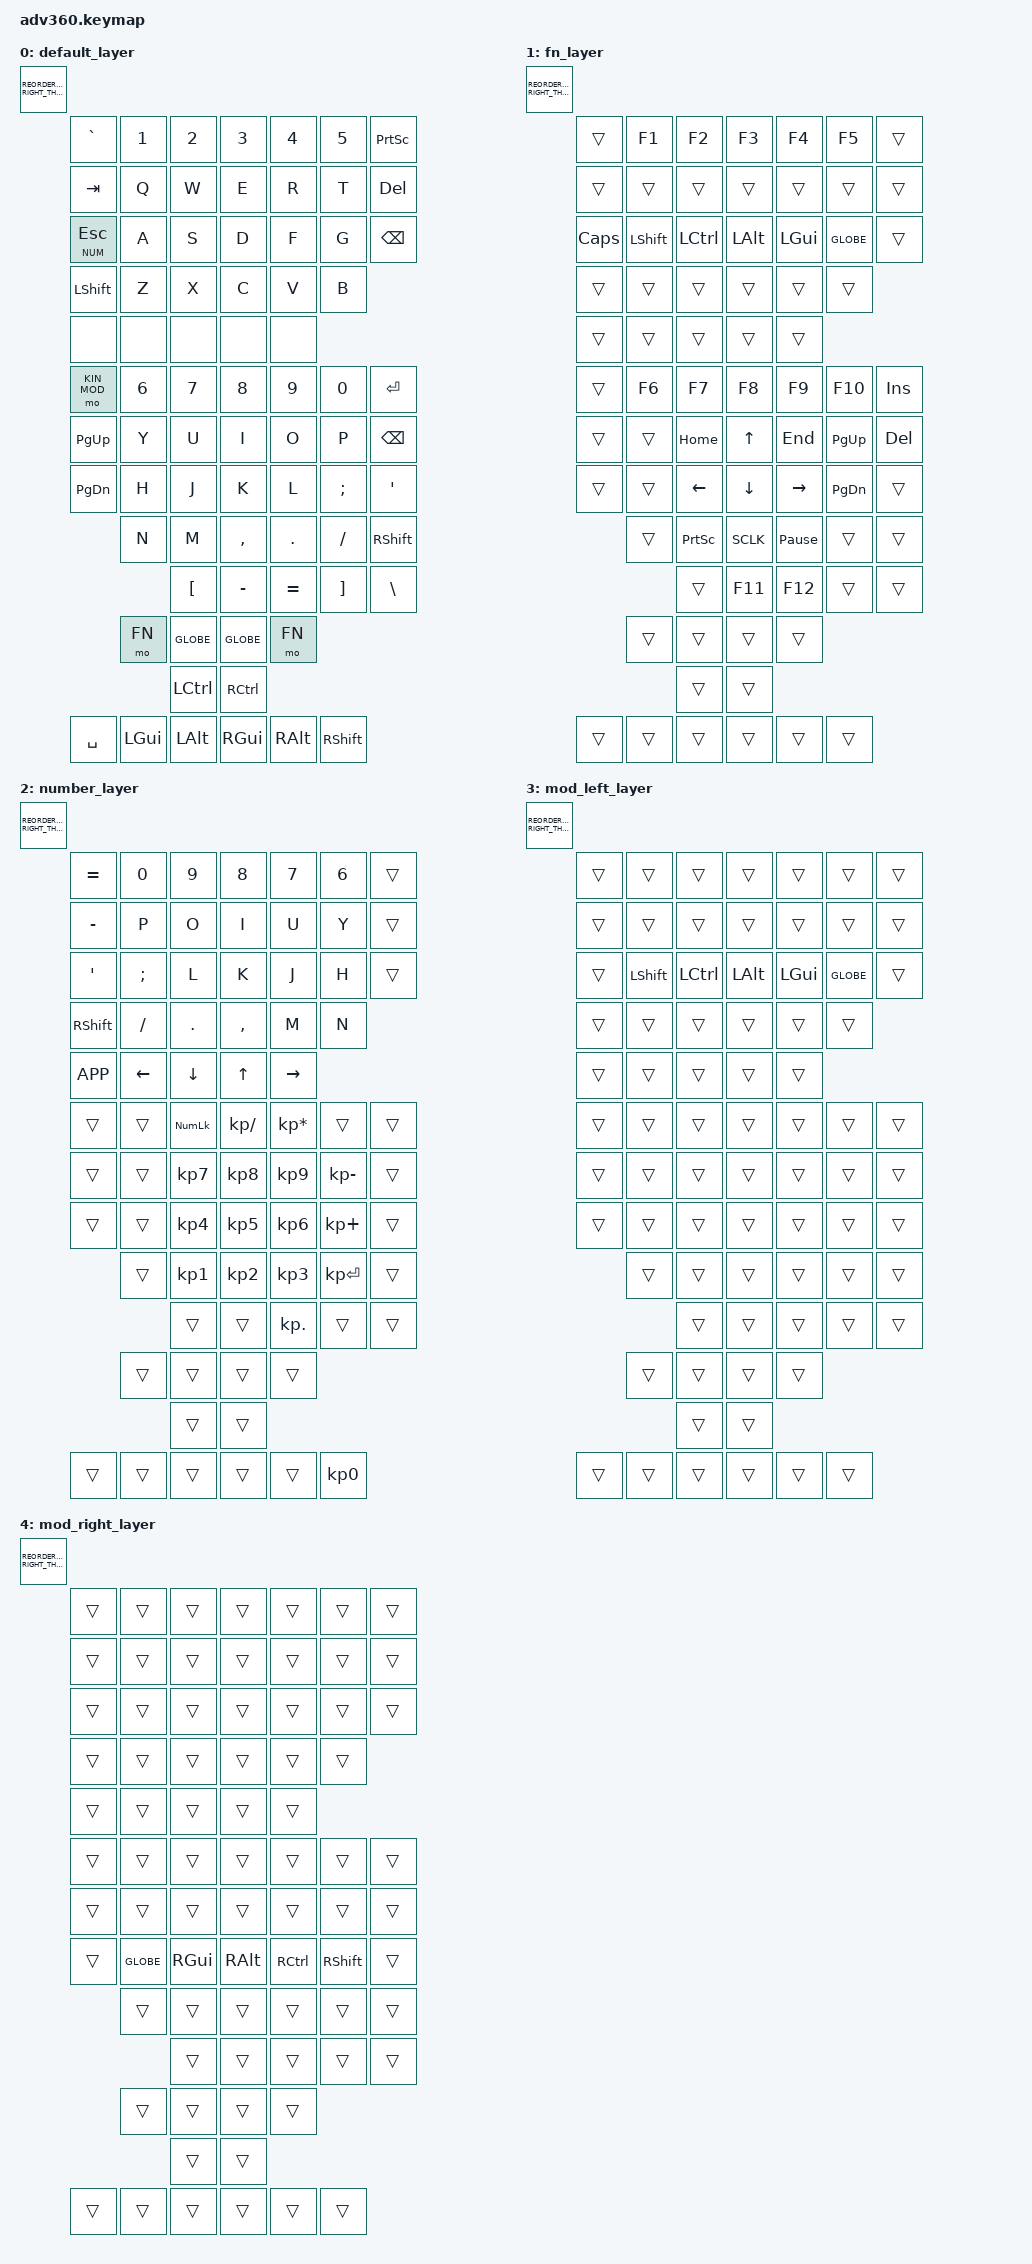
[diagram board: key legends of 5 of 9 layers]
#include <behaviors.dtsi>
#include <dt-bindings/zmk/keys.h>
#include <dt-bindings/zmk/bt.h>
#include <dt-bindings/zmk/rgb.h>
#include <dt-bindings/zmk/stp.h>
#include <dt-bindings/zmk/backlight.h>
#include <dt-bindings/zmk/pointing.h>

// Custom layers
#define DEFAULT 0
#define FN 1
#define NUM 2
#define MOD_LEFT 3
#define MOD_RIGHT 4

// Default Kinesis Advantage 360 Pro layers.
#define KIN_DEF 5
#define KIN_KP 6
#define KIN_FN 7
#define KIN_MOD 8

#define ___ &trans
#define _x_ &none

#define REORDER_LEFT_RIGHT_THUMBS(L1, L2, L3, L4, L5, R1, R2, R3, R4, R5, T3, T4, T5, X) L1 R1 L2 R2 L3 T3 R3 L4 T4 R4 L5 T5 R5

//#include "combos.dtsi"


/ {
    behaviors {
      #include "macros.dtsi"
      #include "version.dtsi"

//      #include "behaviors.dtsi"

      m: mod_hold {
        compatible = "zmk,behavior-hold-tap";
        flavor = "hold-preferred";
        label = "MOD_HOLD";
        #binding-cells = <2>;
        tapping-term-ms = <220>;
        quick-tap-ms = <200>;
        bindings = <&kp>, <&kp>;
      };

      l: layer_hold {
        compatible = "zmk,behavior-hold-tap";
        flavor = "hold-preferred";
        label = "LAYER_HOLD";
        #binding-cells = <2>;
        tapping-term-ms = <220>;
        quick-tap-ms = <200>;
        bindings = <&mo>, <&kp>;
      };
    };

  keymap {
    compatible = "zmk,keymap";

    default_layer {
      bindings = <REORDER_LEFT_RIGHT_THUMBS(
        // ╭─────────────┬─────────────┬─────────────┬─────────────┬─────────────┬─────────────┬─────────────╮
             &kp GRAVE     &kp N1        &kp N2        &kp N3        &kp N4        &kp N5        &kp PSCRN   ,
        // ├─────────────┼─────────────┼─────────────┼─────────────┼─────────────┼─────────────┼─────────────┤
             &kp TAB       &kp Q         &kp W         &kp E         &kp R         &kp T         &kp DEL     ,
        // ├─────────────┼─────────────┼─────────────┼─────────────┼─────────────┼─────────────┼─────────────┤
             &l NUM ESC    &kp A         &kp S         &kp D         &kp F         &kp G         &kp BSPC    ,
        // ├─────────────┼─────────────┼─────────────┼─────────────┼─────────────┼─────────────┼─────────────╯
             &kp LSHFT     &kp Z         &kp X         &kp C         &kp V         &kp B       ,
        // ├─────────────┼─────────────┼─────────────┼─────────────┼─────────────┼─────────────╯
             _x_           _x_           _x_           _x_           _x_         ,
        // ╰─────────────┴─────────────┴─────────────┴─────────────┴─────────────╯
        //
        // ╭─────────────┬─────────────┬─────────────┬─────────────┬─────────────┬─────────────┬─────────────╮
             &mo KIN_MOD   &kp N6        &kp N7        &kp N8        &kp N9        &kp N0        &kp ENTER   ,
        // ├─────────────┼─────────────┼─────────────┼─────────────┼─────────────┼─────────────┼─────────────┤
             &kp PG_UP     &kp Y         &kp U         &kp I         &kp O         &kp P         &kp BSPC    ,
        // ├─────────────┼─────────────┼─────────────┼─────────────┼─────────────┼─────────────┼─────────────┤
             &kp PG_DN     &kp H         &kp J         &kp K         &kp L         &kp SEMI      &kp SQT     ,
        // ╰─────────────┼─────────────┼─────────────┼─────────────┼─────────────┼─────────────┼─────────────┤
                           &kp N         &kp M         &kp COMMA     &kp DOT       &kp FSLH      &kp RSHFT   ,
        //               ╰─────────────┼─────────────┼─────────────┼─────────────┼─────────────┼─────────────┤
                                         &kp LBKT      &kp MINUS     &kp EQUAL     &kp RBKT      &kp BSLH    ,
        //                             ╰─────────────┴─────────────┴─────────────┴─────────────┴─────────────╯
        //
        //               ╭─────────────┬─────────────╮   ╭─────────────┬─────────────╮
                           &mo FN        &kp GLOBE         &kp GLOBE     &mo FN      ,
        // ╭─────────────┼─────────────┼─────────────┤   ├─────────────┼─────────────┼─────────────╮
                                         &kp LCTL          &kp RCTL                                ,
        // │             │             ├─────────────┤   ├─────────────┤             │             │
             &kp SPACE     &kp LGUI      &kp LALT          &kp RGUI      &kp RALT      &kp RSHFT   ,
        // ╰─────────────┴─────────────┴─────────────╯   ╰─────────────┴─────────────┴─────────────╯
      )>;
    };

    fn_layer {
      bindings = <REORDER_LEFT_RIGHT_THUMBS(
        // ╭─────────────┬─────────────┬─────────────┬─────────────┬─────────────┬─────────────┬─────────────╮
             ___           &kp F1        &kp F2        &kp F3        &kp F4        &kp F5        ___         ,
        // ├─────────────┼─────────────┼─────────────┼─────────────┼─────────────┼─────────────┼─────────────┤
             ___           ___           ___           ___           ___           ___           ___         ,
        // ├─────────────┼─────────────┼─────────────┼─────────────┼─────────────┼─────────────┼─────────────┤
             &kp CAPS      &kp LSHFT     &kp LCTRL     &kp LALT      &kp LGUI      &kp GLOBE     ___         ,
        // ├─────────────┼─────────────┼─────────────┼─────────────┼─────────────┼─────────────┼─────────────╯
             ___           ___           ___           ___           ___           ___         ,
        // ├─────────────┼─────────────┼─────────────┼─────────────┼─────────────┼─────────────╯
             ___           ___           ___           ___           ___         ,
        // ╰─────────────┴─────────────┴─────────────┴─────────────┴─────────────╯
        //
        // ╭─────────────┬─────────────┬─────────────┬─────────────┬─────────────┬─────────────┬─────────────╮
             ___           &kp F6        &kp F7        &kp F8        &kp F9        &kp F10       &kp INS     ,
        // ├─────────────┼─────────────┼─────────────┼─────────────┼─────────────┼─────────────┼─────────────┤
             ___           ___           &kp HOME      &kp UP        &kp END       &kp PG_UP     &kp DEL     ,
        // ├─────────────┼─────────────┼─────────────┼─────────────┼─────────────┼─────────────┼─────────────┤
             ___           ___           &kp LEFT      &kp DOWN      &kp RIGHT     &kp PG_DN     ___         ,
        // ╰─────────────┼─────────────┼─────────────┼─────────────┼─────────────┼─────────────┼─────────────┤
                           ___           &kp PSCRN     &kp SCLK    &kp PAUSE_BREAK ___           ___         ,
        //               ╰─────────────┼─────────────┼─────────────┼─────────────┼─────────────┼─────────────┤
                                         ___           &kp F11       &kp F12       ___           ___         ,
        //                             ╰─────────────┴─────────────┴─────────────┴─────────────┴─────────────╯
        //
        //               ╭─────────────┬─────────────╮   ╭─────────────┬─────────────╮
                           ___           ___               ___           ___         ,
        // ╭─────────────┼─────────────┼─────────────┤   ├─────────────┼─────────────┼─────────────╮
                                         ___               ___                                     ,
        // │             │             ├─────────────┤   ├─────────────┤             │             │
             ___           ___           ___               ___           ___           ___         ,
        // ╰─────────────┴─────────────┴─────────────╯   ╰─────────────┴─────────────┴─────────────╯
      )>;
    };

    number_layer {
      bindings = <REORDER_LEFT_RIGHT_THUMBS(
        // ╭─────────────┬─────────────┬─────────────┬─────────────┬─────────────┬─────────────┬─────────────╮
             &kp EQUAL     &kp N0        &kp N9        &kp N8        &kp N7        &kp N6        ___         ,
        // ├─────────────┼─────────────┼─────────────┼─────────────┼─────────────┼─────────────┼─────────────┤
             &kp MINUS     &kp P         &kp O         &kp I         &kp U         &kp Y         ___         ,
        // ├─────────────┼─────────────┼─────────────┼─────────────┼─────────────┼─────────────┼─────────────┤
             &kp SQT       &kp SEMI      &kp L         &kp K         &kp J         &kp H         ___         ,
        // ├─────────────┼─────────────┼─────────────┼─────────────┼─────────────┼─────────────┼─────────────╯
             &kp RSHFT     &kp FSLH      &kp DOT       &kp COMMA     &kp M         &kp N       ,
        // ├─────────────┼─────────────┼─────────────┼─────────────┼─────────────┼─────────────╯
             &kp K_APP     &kp LEFT      &kp DOWN      &kp UP        &kp RIGHT   ,
        // ╰─────────────┴─────────────┴─────────────┴─────────────┴─────────────╯
        //
        // ╭─────────────┬─────────────┬─────────────┬─────────────┬─────────────┬─────────────┬─────────────╮
             ___           ___           &kp KP_NUM    &kp KP_DIVIDE &kp KP_MULTIPLY ___         ___         ,
        // ├─────────────┼─────────────┼─────────────┼─────────────┼─────────────┼─────────────┼─────────────┤
             ___           ___           &kp KP_N7     &kp KP_N8     &kp KP_N9     &kp KP_MINUS  ___         ,
        // ├─────────────┼─────────────┼─────────────┼─────────────┼─────────────┼─────────────┼─────────────┤
             ___           ___           &kp KP_N4     &kp KP_N5     &kp KP_N6     &kp KP_PLUS   ___         ,
        // ╰─────────────┼─────────────┼─────────────┼─────────────┼─────────────┼─────────────┼─────────────┤
                           ___           &kp KP_N1     &kp KP_N2     &kp KP_N3     &kp KP_ENTER  ___         ,
        //               ╰─────────────┼─────────────┼─────────────┼─────────────┼─────────────┼─────────────┤
                                         ___           ___           &kp KP_DOT    ___           ___         ,
        //                             ╰─────────────┴─────────────┴─────────────┴─────────────┴─────────────╯
        //
        //               ╭─────────────┬─────────────╮   ╭─────────────┬─────────────╮
                           ___           ___               ___           ___         ,
        // ╭─────────────┼─────────────┼─────────────┤   ├─────────────┼─────────────┼─────────────╮
                                         ___               ___                                     ,
        // │             │             ├─────────────┤   ├─────────────┤             │             │
             ___           ___           ___               ___           ___           &kp KP_N0   ,
        // ╰─────────────┴─────────────┴─────────────╯   ╰─────────────┴─────────────┴─────────────╯
      )>;
    };

    mod_left_layer {
      bindings = <REORDER_LEFT_RIGHT_THUMBS(
        // ╭─────────────┬─────────────┬─────────────┬─────────────┬─────────────┬─────────────┬─────────────╮
             ___           ___           ___           ___           ___           ___           ___         ,
        // ├─────────────┼─────────────┼─────────────┼─────────────┼─────────────┼─────────────┼─────────────┤
             ___           ___           ___           ___           ___           ___           ___         ,
        // ├─────────────┼─────────────┼─────────────┼─────────────┼─────────────┼─────────────┼─────────────┤
             ___           &kp LSHFT     &kp LCTRL     &kp LALT      &kp LGUI      &kp GLOBE     ___         ,
        // ├─────────────┼─────────────┼─────────────┼─────────────┼─────────────┼─────────────┼─────────────╯
             ___           ___           ___           ___           ___           ___         ,
        // ├─────────────┼─────────────┼─────────────┼─────────────┼─────────────┼─────────────╯
             ___           ___           ___           ___           ___         ,
        // ╰─────────────┴─────────────┴─────────────┴─────────────┴─────────────╯
        //
        // ╭─────────────┬─────────────┬─────────────┬─────────────┬─────────────┬─────────────┬─────────────╮
             ___           ___           ___           ___           ___           ___           ___         ,
        // ├─────────────┼─────────────┼─────────────┼─────────────┼─────────────┼─────────────┼─────────────┤
             ___           ___           ___           ___           ___           ___           ___         ,
        // ├─────────────┼─────────────┼─────────────┼─────────────┼─────────────┼─────────────┼─────────────┤
             ___           ___           ___           ___           ___           ___           ___         ,
        // ╰─────────────┼─────────────┼─────────────┼─────────────┼─────────────┼─────────────┼─────────────┤
                           ___           ___           ___           ___           ___           ___         ,
        //               ╰─────────────┼─────────────┼─────────────┼─────────────┼─────────────┼─────────────┤
                                         ___           ___           ___           ___           ___         ,
        //                             ╰─────────────┴─────────────┴─────────────┴─────────────┴─────────────╯
        //
        //               ╭─────────────┬─────────────╮   ╭─────────────┬─────────────╮
                           ___           ___               ___           ___         ,
        // ╭─────────────┼─────────────┼─────────────┤   ├─────────────┼─────────────┼─────────────╮
                                         ___               ___                                     ,
        // │             │             ├─────────────┤   ├─────────────┤             │             │
             ___           ___           ___               ___           ___           ___         ,
        // ╰─────────────┴─────────────┴─────────────╯   ╰─────────────┴─────────────┴─────────────╯
      )>;
    };

    mod_right_layer {
      bindings = <REORDER_LEFT_RIGHT_THUMBS(
        // ╭─────────────┬─────────────┬─────────────┬─────────────┬─────────────┬─────────────┬─────────────╮
             ___           ___           ___           ___           ___           ___           ___         ,
        // ├─────────────┼─────────────┼─────────────┼─────────────┼─────────────┼─────────────┼─────────────┤
             ___           ___           ___           ___           ___           ___           ___         ,
        // ├─────────────┼─────────────┼─────────────┼─────────────┼─────────────┼─────────────┼─────────────┤
             ___           ___           ___           ___           ___           ___           ___         ,
        // ├─────────────┼─────────────┼─────────────┼─────────────┼─────────────┼─────────────┼─────────────╯
             ___           ___           ___           ___           ___           ___         ,
        // ├─────────────┼─────────────┼─────────────┼─────────────┼─────────────┼─────────────╯
             ___           ___           ___           ___           ___         ,
        // ╰─────────────┴─────────────┴─────────────┴─────────────┴─────────────╯
        //
        // ╭─────────────┬─────────────┬─────────────┬─────────────┬─────────────┬─────────────┬─────────────╮
             ___           ___           ___           ___           ___           ___           ___         ,
        // ├─────────────┼─────────────┼─────────────┼─────────────┼─────────────┼─────────────┼─────────────┤
             ___           ___           ___           ___           ___           ___           ___         ,
        // ├─────────────┼─────────────┼─────────────┼─────────────┼─────────────┼─────────────┼─────────────┤
             ___           &kp GLOBE     &kp RGUI      &kp RALT      &kp RCTRL     &kp RSHFT     ___         ,
        // ╰─────────────┼─────────────┼─────────────┼─────────────┼─────────────┼─────────────┼─────────────┤
                           ___           ___           ___           ___           ___           ___         ,
        //               ╰─────────────┼─────────────┼─────────────┼─────────────┼─────────────┼─────────────┤
                                         ___           ___           ___           ___           ___         ,
        //                             ╰─────────────┴─────────────┴─────────────┴─────────────┴─────────────╯
        //
        //               ╭─────────────┬─────────────╮   ╭─────────────┬─────────────╮
                           ___           ___               ___           ___         ,
        // ╭─────────────┼─────────────┼─────────────┤   ├─────────────┼─────────────┼─────────────╮
                                         ___               ___                                     ,
        // │             │             ├─────────────┤   ├─────────────┤             │             │
             ___           ___           ___               ___           ___           ___         ,
        // ╰─────────────┴─────────────┴─────────────╯   ╰─────────────┴─────────────┴─────────────╯
      )>;
    };


    // Default Kinesis Advantage 360 Pro layers.
    kinesis_default_layer {
      display-name = "Base";
      bindings = <
        // ╭─────────────┬─────────────┬─────────────┬─────────────┬─────────────┬─────────────┬─────────────╮                                                                                             ╭─────────────┬─────────────┬─────────────┬─────────────┬─────────────┬─────────────┬─────────────╮
             &kp EQUAL     &kp N1        &kp N2        &kp N3        &kp N4        &kp N5        &tog KIN_KP                                                                                                 &mo KIN_MOD   &kp N6        &kp N7        &kp N8        &kp N9        &kp N0        &kp MINUS
        // ├─────────────┼─────────────┼─────────────┼─────────────┼─────────────┼─────────────┼─────────────┤                                                                                             ├─────────────┼─────────────┼─────────────┼─────────────┼─────────────┼─────────────┼─────────────┤
             &kp TAB       &kp Q         &kp W         &kp E         &kp R         &kp T         _x_                                                                                                         _x_           &kp Y         &kp U         &kp I         &kp O         &kp P         &kp BSLH
        // ├─────────────┼─────────────┼─────────────┼─────────────┼─────────────┼─────────────┼─────────────┤                ╭─────────────┬─────────────╮   ╭─────────────┬─────────────╮                ├─────────────┼─────────────┼─────────────┼─────────────┼─────────────┼─────────────┼─────────────┤
             &kp ESC       &kp A         &kp S         &kp D         &kp F         &kp G         _x_                            &kp LCTRL     &kp LALT          &kp LGUI      &kp RCTRL                      _x_           &kp H         &kp J         &kp K         &kp L         &kp SEMI      &kp SQT
        // ├─────────────┼─────────────┼─────────────┼─────────────┼─────────────┼─────────────┼─────────────╯  ╭─────────────┼─────────────┼─────────────┤   ├─────────────┼─────────────┼─────────────╮  ╰─────────────┼─────────────┼─────────────┼─────────────┼─────────────┼─────────────┼─────────────┤
             &kp LSHFT     &kp Z         &kp X         &kp C         &kp V         &kp B                                                      &kp HOME          &kp PG_UP                                                  &kp N         &kp M         &kp COMMA     &kp DOT       &kp FSLH      &kp RSHFT
        // ├─────────────┼─────────────┼─────────────┼─────────────┼─────────────┼─────────────╯                │             │             ├─────────────┤   ├─────────────┤             │             │                ╰─────────────┼─────────────┼─────────────┼─────────────┼─────────────┼─────────────┤
             &mo KIN_FN    &kp GRAVE     &kp CAPS      &kp LEFT      &kp RIGHT                                    &kp BSPC      &kp DEL       &kp END           &kp PG_DN     &kp ENTER     &kp SPACE                                    &kp UP        &kp DOWN      &kp LBKT      &kp RBKT      &mo KIN_FN
        // ╰─────────────┴─────────────┴─────────────┴─────────────┴─────────────╯                              ╰─────────────┴─────────────┴─────────────╯   ╰─────────────┴─────────────┴─────────────╯                              ╰─────────────┴─────────────┴─────────────┴─────────────┴─────────────╯
      >;
    };
    kinesis_keypad {
      display-name = "Kp";
      bindings = <
        // ╭─────────────┬─────────────┬─────────────┬─────────────┬─────────────┬─────────────┬─────────────╮                                                                                             ╭─────────────┬─────────────┬─────────────┬─────────────┬─────────────┬─────────────┬─────────────╮
             &kp EQUAL     &kp N1        &kp N2        &kp N3        &kp N4        &kp N5        ___                                                                                                         &mo KIN_MOD   &kp N6        &kp KP_NUM    &kp KP_EQUAL  &kp KP_DIVIDE &kp KP_MULTIPLY &kp MINUS
        // ├─────────────┼─────────────┼─────────────┼─────────────┼─────────────┼─────────────┼─────────────┤                                                                                             ├─────────────┼─────────────┼─────────────┼─────────────┼─────────────┼─────────────┼─────────────┤
             &kp TAB       &kp Q         &kp W         &kp E         &kp R         &kp T         _x_                                                                                                         _x_           &kp Y         &kp KP_N7     &kp KP_N8     &kp KP_N9     &kp KP_MINUS  &kp BSLH
        // ├─────────────┼─────────────┼─────────────┼─────────────┼─────────────┼─────────────┼─────────────┤                ╭─────────────┬─────────────╮   ╭─────────────┬─────────────╮                ├─────────────┼─────────────┼─────────────┼─────────────┼─────────────┼─────────────┼─────────────┤
             &kp ESC       &kp A         &kp S         &kp D         &kp F         &kp G         _x_                            &kp LCTRL     &kp LALT          &kp LGUI      &kp RCTRL                      _x_           &kp H         &kp KP_N4     &kp KP_N5     &kp KP_N6     &kp KP_PLUS   &kp SQT
        // ├─────────────┼─────────────┼─────────────┼─────────────┼─────────────┼─────────────┼─────────────╯  ╭─────────────┼─────────────┼─────────────┤   ├─────────────┼─────────────┼─────────────╮  ╰─────────────┼─────────────┼─────────────┼─────────────┼─────────────┼─────────────┼─────────────┤
             &kp LSHFT     &kp Z         &kp X         &kp C         &kp V         &kp B                                                      &kp HOME          &kp PG_UP                                                  &kp N         &kp KP_N1     &kp KP_N2     &kp KP_N3     &kp KP_ENTER  &kp RSHFT
        // ├─────────────┼─────────────┼─────────────┼─────────────┼─────────────┼─────────────╯                │             │             ├─────────────┤   ├─────────────┤             │             │                ╰─────────────┼─────────────┼─────────────┼─────────────┼─────────────┼─────────────┤
             &mo KIN_FN    &kp GRAVE     &kp CAPS      &kp LEFT      &kp RIGHT                                    &kp BSPC      &kp DEL       &kp END           &kp PG_DN     &kp ENTER     &kp KP_N0                                    &kp UP        &kp DOWN      &kp KP_DOT    &kp RBKT      &mo KIN_FN
        // ╰─────────────┴─────────────┴─────────────┴─────────────┴─────────────╯                              ╰─────────────┴─────────────┴─────────────╯   ╰─────────────┴─────────────┴─────────────╯                              ╰─────────────┴─────────────┴─────────────┴─────────────┴─────────────╯
      >;
    };
    kinesis_fn {
      display-name = "Fn";
      bindings = <
        // ╭─────────────┬─────────────┬─────────────┬─────────────┬─────────────┬─────────────┬─────────────╮                                                                                             ╭─────────────┬─────────────┬─────────────┬─────────────┬─────────────┬─────────────┬─────────────╮
             &kp F1        &kp F2        &kp F3        &kp F4        &kp F5        &kp F6        &tog KIN_KP                                                                                                 &mo KIN_MOD   &kp F7        &kp F8        &kp F9        &kp F10       &kp F11       &kp F12
        // ├─────────────┼─────────────┼─────────────┼─────────────┼─────────────┼─────────────┼─────────────┤                                                                                             ├─────────────┼─────────────┼─────────────┼─────────────┼─────────────┼─────────────┼─────────────┤
             ___           ___           ___           ___           ___           ___           _x_                                                                                                         _x_           ___           ___           ___           ___           ___           ___
        // ├─────────────┼─────────────┼─────────────┼─────────────┼─────────────┼─────────────┼─────────────┤                ╭─────────────┬─────────────╮   ╭─────────────┬─────────────╮                ├─────────────┼─────────────┼─────────────┼─────────────┼─────────────┼─────────────┼─────────────┤
             ___           ___           ___           ___           ___           ___           _x_                            ___           ___               ___           ___                            _x_           ___           ___           ___           ___           ___           ___
        // ├─────────────┼─────────────┼─────────────┼─────────────┼─────────────┼─────────────┼─────────────╯  ╭─────────────┼─────────────┼─────────────┤   ├─────────────┼─────────────┼─────────────╮  ╰─────────────┼─────────────┼─────────────┼─────────────┼─────────────┼─────────────┼─────────────┤
             ___           ___           ___           ___           ___           ___                                                        ___               ___                                                        ___           ___           ___           ___           ___           ___
        // ├─────────────┼─────────────┼─────────────┼─────────────┼─────────────┼─────────────╯                │             │             ├─────────────┤   ├─────────────┤             │             │                ╰─────────────┼─────────────┼─────────────┼─────────────┼─────────────┼─────────────┤
             ___           ___           ___           ___           ___                                          ___           ___           ___               ___           ___           ___                                          ___           ___           ___           ___           ___
        // ╰─────────────┴─────────────┴─────────────┴─────────────┴─────────────╯                              ╰─────────────┴─────────────┴─────────────╯   ╰─────────────┴─────────────┴─────────────╯                              ╰─────────────┴─────────────┴─────────────┴─────────────┴─────────────╯
      >;
    };
    kinesis_mod {
      display-name = "Mod";
      bindings = <
        // ╭─────────────┬─────────────┬─────────────┬─────────────┬─────────────┬─────────────┬─────────────╮                                                                                             ╭─────────────┬─────────────┬─────────────┬─────────────┬─────────────┬─────────────┬─────────────╮
             _x_           &bt BT_SEL 0  &bt BT_SEL 1  &bt BT_SEL 2  &bt BT_SEL 3  &bt BT_SEL 4  _x_                                                                                                         ___           _x_           _x_           _x_           _x_           _x_           _x_
        // ├─────────────┼─────────────┼─────────────┼─────────────┼─────────────┼─────────────┼─────────────┤                                                                                             ├─────────────┼─────────────┼─────────────┼─────────────┼─────────────┼─────────────┼─────────────┤
             _x_           _x_           _x_           _x_           _x_           _x_           &bootloader                                                                                                 &bootloader   _x_           _x_           _x_           _x_           _x_           _x_
        // ├─────────────┼─────────────┼─────────────┼─────────────┼─────────────┼─────────────┼─────────────┤                ╭─────────────┬─────────────╮   ╭─────────────┬─────────────╮                ├─────────────┼─────────────┼─────────────┼─────────────┼─────────────┼─────────────┼─────────────┤
            &studio_unlock _x_           _x_           &to DEFAULT   _x_           _x_           _x_                            _x_           _x_               &bt BT_CLR    _x_                            &stp STP_BAT  _x_           _x_           &to KIN_DEF   _x_           _x_           _x_
        // ├─────────────┼─────────────┼─────────────┼─────────────┼─────────────┼─────────────┼─────────────╯  ╭─────────────┼─────────────┼─────────────┤   ├─────────────┼─────────────┼─────────────╮  ╰─────────────┼─────────────┼─────────────┼─────────────┼─────────────┼─────────────┼─────────────┤
             _x_           _x_           _x_           _x_           &macro_ver    _x_                                                        _x_               _x_                                                        _x_           _x_           _x_           _x_           _x_           _x_
        // ├─────────────┼─────────────┼─────────────┼─────────────┼─────────────┼─────────────╯                │             │             ├─────────────┤   ├─────────────┤             │             │                ╰─────────────┼─────────────┼─────────────┼─────────────┼─────────────┼─────────────┤
             _x_           _x_           _x_           _x_           _x_                                          _x_           _x_           _x_               _x_           &bl BL_TOG    &rgb_ug RGB_TOG                              &bl BL_INC    &bl BL_DEC    _x_           _x_           _x_
        // ╰─────────────┴─────────────┴─────────────┴─────────────┴─────────────╯                              ╰─────────────┴─────────────┴─────────────╯   ╰─────────────┴─────────────┴─────────────╯                              ╰─────────────┴─────────────┴─────────────┴─────────────┴─────────────╯
      >;
    };
    extra1 {
      display-name = "Red";
      status = "reserved";
    };

    extra2 {
      display-name = "Purple";
      status = "reserved";
    };

    extra3 {
      display-name = "Cyan";
      status = "reserved";
    };

    extra4 {
      display-name = "Yellow";
      status = "reserved";
    };
  };
};
